# R7FA4W1AD register map
Vendor: Renesas; Series: RA4; File version: 1.0
CPU: CM4 r0p1, little endian, MPU, FPU, VTOR, 4 interrupt priority bits
Registers are 8-bit, read-write, reset 0x0 unless marked. A register's access mark holds for its fields unless they carry their own. Offsets are from the block's base; [hi:lo] are bit positions; {n}, {i} and the like mark numbered series.

## SPI0 — Serial Peripheral Interface 0
Base 0x40072000
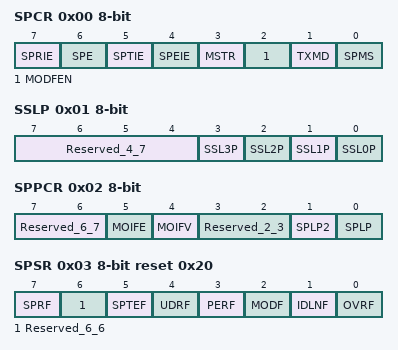
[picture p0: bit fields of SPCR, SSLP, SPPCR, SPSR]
0x00 SPCR — SPI Control Register
  [7] SPRIE — SPI Receive Buffer Full Interrupt Enable
  [6] SPE — SPI Function Enable
  [5] SPTIE — Transmit Buffer Empty Interrupt Enable
  [4] SPEIE — SPI Error Interrupt Enable
  [3] MSTR — SPI Master/Slave Mode Select
  [2] MODFEN — Mode Fault Error Detection Enable
  [1] TXMD — Communications Operating Mode Select
  [0] SPMS — SPI Mode Select
0x01 SSLP — SPI Slave Select Polarity Register
  [7:4] Reserved_4_7 — These bits are read as 0000. The write value should be 0000.
  [n] SSL{n}P (n=0..3) — SSL{n} Signal Polarity Setting
0x02 SPPCR — SPI Pin Control Register
  [7:6] Reserved_6_7 — These bits are read as 00. The write value should be 00.
  [5] MOIFE — MOSI Idle Value Fixing Enable
  [4] MOIFV — MOSI Idle Fixed Value
  [3:2] Reserved_2_3 — These bits are read as 00. The write value should be 00.
  [1] SPLP2 — RSPI Loopback 2
  [0] SPLP — RSPI Loopback
0x03 SPSR reset 0x20 — SPI Status Register
  [7] SPRF write-0-clears read-modifies — SPI Receive Buffer Full Flag
  [6] Reserved_6_6 — This bit is read as 0. The write value should be 0.
  [5] SPTEF write-0-clears read-modifies — SPI Transmit Buffer Empty Flag
  [4] UDRF write-0-clears read-modifies — Underrun Error Flag(When MODF is 0, This bit is invalid.)
  [3] PERF write-0-clears read-modifies — Parity Error Flag
  [2] MODF write-0-clears read-modifies — Mode Fault Error Flag
  [1] IDLNF ro — SPI Idle Flag
  [0] OVRF write-0-clears read-modifies — Overrun Error Flag
0x04 SPDR 32-bit — SPI Data Register
  [31:0] SPDR — SPDR is the interface with the buffers that hold data for transmission and reception by the RSPI.When accessing in word (SPDCR.SPLW=1), access SPDR.
0x04 SPDR_HA 16-bit (alternate view of SPDR) — SPI Data Register ( halfword access )
  [15:0] SPDR_HA — SPDR is the interface with the buffers that hold data for transmission and reception by the RSPI.When accessing in halfword (SPDCR.SPLW=0), access SPDR_HA.
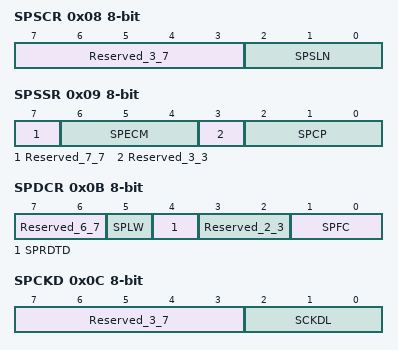
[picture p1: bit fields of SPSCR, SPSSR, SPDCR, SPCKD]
0x08 SPSCR — SPI Sequence Control Register
  [7:3] Reserved_3_7 — These bits are read as 00000. The write value should be 00000.
  [2:0] SPSLN — RSPI Sequence Length SpecificationThe order in which the SPCMD0 to SPCMD07 registers are to be referenced is changed in accordance with the sequence length that is set in these bits. The relationship among the setting of these bits, sequence length, and SPCMD0 to SPCMD7 registers referenced by the RSPI is shown above. However, the RSPI in slave mode always references SPCMD0.
0x09 SPSSR ro — SPI Sequence Status Register
  [7] Reserved_7_7 — This bit is read as 0.
  [6:4] SPECM — SPI Error Command
  [3] Reserved_3_3 — This bit is read as 0.
  [2:0] SPCP — SPI Command Pointer
0x0A SPBR reset 0xFF — SPI Bit Rate Register
  [7:0] SPR — SPBR sets the bit rate in master mode.
0x0B SPDCR — SPI Data Control Register
  [7:6] Reserved_6_7 — These bits are read as 00. The write value should be 00.
  [5] SPLW — SPI Word Access/Halfword Access Specification
  [4] SPRDTD — RSPI Receive/Transmit Data Selection
  [3:2] Reserved_2_3 — These bits are read as 00. The write value should be 00.
  [1:0] SPFC — Number of Frames Specification
0x0C SPCKD — SPI Clock Delay Register
  [7:3] Reserved_3_7 — These bits are read as 00000. The write value should be 00000.
  [2:0] SCKDL — RSPCK Delay Setting
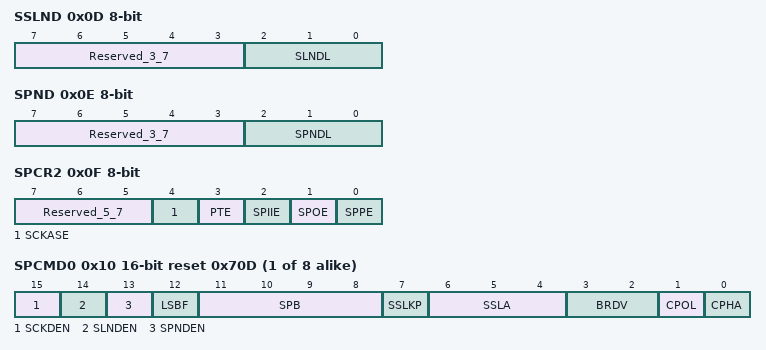
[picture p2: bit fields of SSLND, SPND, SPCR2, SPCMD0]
0x0D SSLND — SPI Slave Select Negation Delay Register
  [7:3] Reserved_3_7 — These bits are read as 00000. The write value should be 00000.
  [2:0] SLNDL — SSL Negation Delay Setting
0x0E SPND — SPI Next,Access Delay Register
  [7:3] Reserved_3_7 — These bits are read as 00000. The write value should be 00000.
  [2:0] SPNDL — SPI Next,Access Delay Setting
0x0F SPCR2 — SPI Control Register 2
  [7:5] Reserved_5_7 — These bits are read as 000. The write value should be 000.
  [4] SCKASE — RSPCK Auto,Stop Function Enable
  [3] PTE — Parity Self,Testing
  [2] SPIIE — SPI Idle Interrupt Enable
  [1] SPOE — Parity Mode
  [0] SPPE — Parity Enable
{0x10+2i} SPCMD{i} (i=0..7) 16-bit reset 0x70D — SPI Command Register {i}
  [15] SCKDEN — RSPCK Delay Setting Enable
  [14] SLNDEN — SSL Negation Delay Setting Enable
  [13] SPNDEN — RSPI Next,Access Delay Enable
  [12] LSBF — RSPI LSB First
  [11:8] SPB — RSPI Data Length Setting
  [7] SSLKP — SSL Signal Level Keeping
  [6:4] SSLA — SSL Signal Assertion Setting
  [3:2] BRDV — Bit Rate Division Setting
  [1] CPOL — RSPCK Polarity Setting
  [0] CPHA — RSPCK Phase Setting

## SPI1 — Serial Peripheral Interface 1
Base 0x40072100
Registers as SPI0, without SPSCR, SPSSR, SPCMD*; these are added or differ:
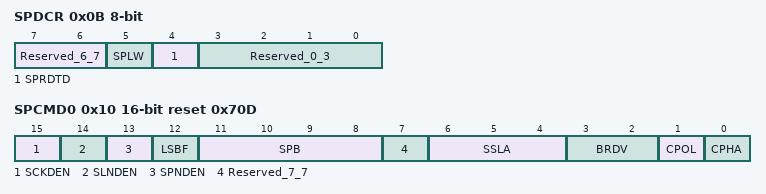
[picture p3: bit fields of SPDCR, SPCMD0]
0x0B SPDCR — SPI Data Control Register
  [7:6] Reserved_6_7 — These bits are read as 00. The write value should be 00.
  [5] SPLW — SPI Word Access/Halfword Access Specification
  [4] SPRDTD — RSPI Receive/Transmit Data Selection
  [3:0] Reserved_0_3 — These bits are read as 0000. The write value should be 0000.
0x10 SPCMD0 16-bit reset 0x70D — SPI Command Register 0
  [15] SCKDEN — RSPCK Delay Setting Enable
  [14] SLNDEN — SSL Negation Delay Setting Enable
  [13] SPNDEN — RSPI Next,Access Delay Enable
  [12] LSBF — RSPI LSB First
  [11:8] SPB — RSPI Data Length Setting
  [7] Reserved_7_7 — This bit is read as 0. The write value should be 0.
  [6:4] SSLA — SSL Signal Assertion Setting
  [3:2] BRDV — Bit Rate Division Setting
  [1] CPOL — RSPCK Polarity Setting
  [0] CPHA — RSPCK Phase Setting
